AUTOSAR XML (schema 4-2-2)
package /SensorActuator_PWM
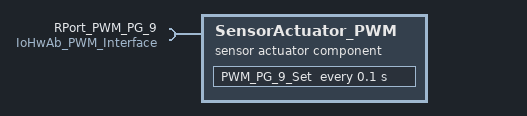
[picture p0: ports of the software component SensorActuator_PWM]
  sensor actuator sw component type SensorActuator_PWM
    require port RPort_PWM_PG_9: required-interface=IoHwAb_PWM_Interface
    behavior IB_SensorActuator_PWM
      timing event TimingEvent_0: start-on-event=PWM_PG_9_Set, period=0.1
      runnable PWM_PG_9_Set: symbol=PWM_PG_9_Set_func
        sync call SynchronousServerCallPoint_0: operation=RPort_PWM_PG_9.IoHwAb_PWM_Set
